# iostm32f205zx register map
Registers are 32-bit, access not given, no defined reset value unless marked. A register's access mark holds for its fields unless they carry their own. Addresses are absolute; registers are grouped by the start of their names; [hi:lo] are bit positions.

## TIM6
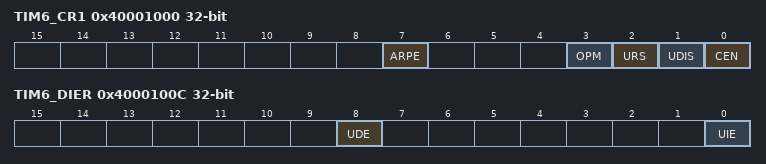
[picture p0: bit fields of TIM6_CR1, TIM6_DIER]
0x40001000 TIM6_CR1
  [7] ARPE, [3] OPM, [2] URS, [1] UDIS, [0] CEN
0x40001004 TIM6_CR2
  [6:4] MMS
0x4000100C TIM6_DIER
  [8] UDE, [0] UIE
0x40001010 TIM6_SR
  [0] UIF
0x40001014 TIM6_EGR
  [0] UG
0x40001024 TIM6_CNT
  [15:0] CNT
0x40001028 TIM6_PSC
  [15:0] PSC
0x4000102C TIM6_ARR
  [15:0] ARR

## TIM7
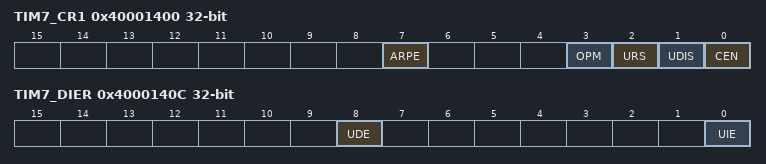
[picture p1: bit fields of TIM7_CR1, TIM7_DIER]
0x40001400 TIM7_CR1
  [7] ARPE, [3] OPM, [2] URS, [1] UDIS, [0] CEN
0x40001404 TIM7_CR2
  [6:4] MMS
0x4000140C TIM7_DIER
  [8] UDE, [0] UIE
0x40001410 TIM7_SR
  [0] UIF
0x40001414 TIM7_EGR
  [0] UG
0x40001424 TIM7_CNT
  [15:0] CNT
0x40001428 TIM7_PSC
  [15:0] PSC
0x4000142C TIM7_ARR
  [15:0] ARR

## TIM9
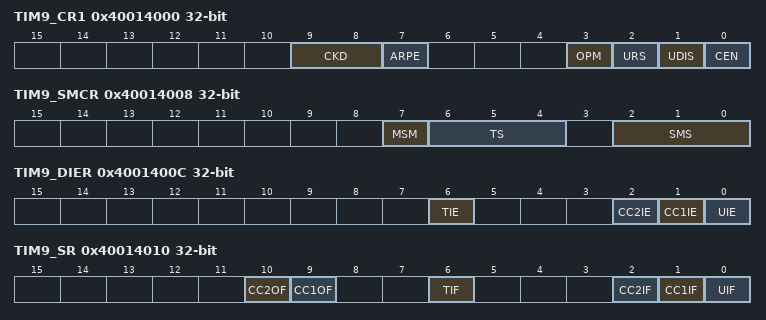
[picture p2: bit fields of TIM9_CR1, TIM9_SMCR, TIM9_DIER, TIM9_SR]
0x40014000 TIM9_CR1
  [9:8] CKD, [7] ARPE, [3] OPM, [2] URS, [1] UDIS, [0] CEN
0x40014004 TIM9_CR2
  [6:4] MMS
0x40014008 TIM9_SMCR
  [7] MSM, [6:4] TS, [2:0] SMS
0x4001400C TIM9_DIER
  [6] TIE, [2] CC2IE, [1] CC1IE, [0] UIE
0x40014010 TIM9_SR
  [10] CC2OF, [9] CC1OF, [6] TIF, [2] CC2IF, [1] CC1IF, [0] UIF
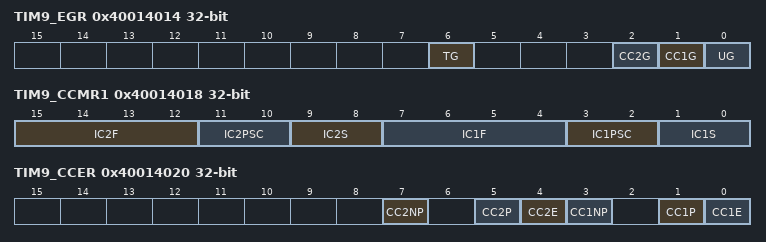
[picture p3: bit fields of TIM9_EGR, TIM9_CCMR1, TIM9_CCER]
0x40014014 TIM9_EGR
  [6] TG, [2] CC2G, [1] CC1G, [0] UG
0x40014018 TIM9_CCMR1
  [15:12] IC2F, [11:10] IC2PSC, [9:8] IC2S, [7:4] IC1F, [3:2] IC1PSC, [1:0] IC1S
0x40014018 TIM9_OCMR1
0x40014020 TIM9_CCER
  [7] CC2NP, [5] CC2P, [4] CC2E, [3] CC1NP, [1] CC1P, [0] CC1E
0x40014024 TIM9_CNT
  [15:0] CNT
0x40014028 TIM9_PSC
  [15:0] PSC
0x4001402C TIM9_ARR
  [15:0] ARR
0x40014034 TIM9_CCR1
  [15:0] CCR
0x40014038 TIM9_CCR2
  [15:0] CCR

## TIM12
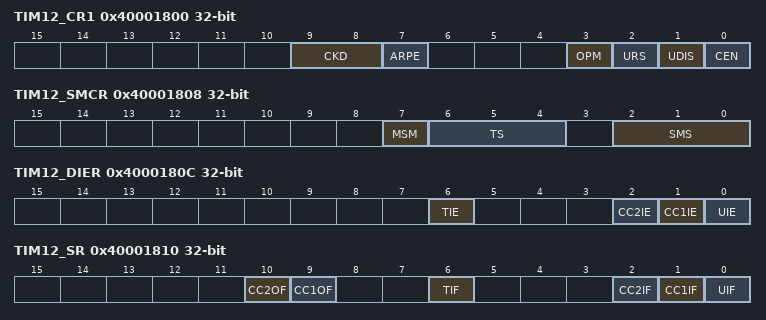
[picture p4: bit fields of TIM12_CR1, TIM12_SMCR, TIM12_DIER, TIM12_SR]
0x40001800 TIM12_CR1
  [9:8] CKD, [7] ARPE, [3] OPM, [2] URS, [1] UDIS, [0] CEN
0x40001804 TIM12_CR2
  [6:4] MMS
0x40001808 TIM12_SMCR
  [7] MSM, [6:4] TS, [2:0] SMS
0x4000180C TIM12_DIER
  [6] TIE, [2] CC2IE, [1] CC1IE, [0] UIE
0x40001810 TIM12_SR
  [10] CC2OF, [9] CC1OF, [6] TIF, [2] CC2IF, [1] CC1IF, [0] UIF
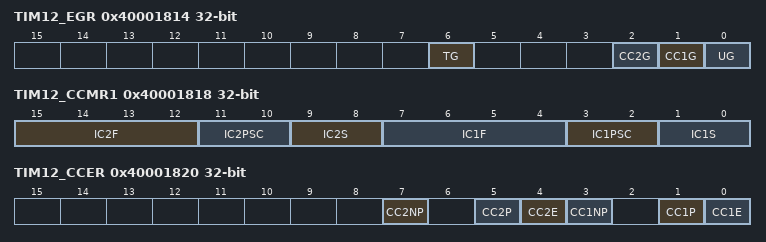
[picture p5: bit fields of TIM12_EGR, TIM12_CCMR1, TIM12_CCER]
0x40001814 TIM12_EGR
  [6] TG, [2] CC2G, [1] CC1G, [0] UG
0x40001818 TIM12_CCMR1
  [15:12] IC2F, [11:10] IC2PSC, [9:8] IC2S, [7:4] IC1F, [3:2] IC1PSC, [1:0] IC1S
0x40001818 TIM12_OCMR1
0x40001820 TIM12_CCER
  [7] CC2NP, [5] CC2P, [4] CC2E, [3] CC1NP, [1] CC1P, [0] CC1E
0x40001824 TIM12_CNT
  [15:0] CNT
0x40001828 TIM12_PSC
  [15:0] PSC
0x4000182C TIM12_ARR
  [15:0] ARR
0x40001834 TIM12_CCR1
  [15:0] CCR
0x40001838 TIM12_CCR2
  [15:0] CCR

## TIM10
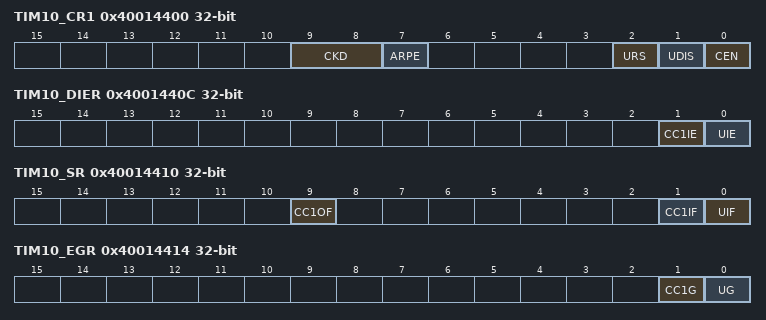
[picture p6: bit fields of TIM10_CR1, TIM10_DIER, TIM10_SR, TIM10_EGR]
0x40014400 TIM10_CR1
  [9:8] CKD, [7] ARPE, [2] URS, [1] UDIS, [0] CEN
0x4001440C TIM10_DIER
  [1] CC1IE, [0] UIE
0x40014410 TIM10_SR
  [9] CC1OF, [1] CC1IF, [0] UIF
0x40014414 TIM10_EGR
  [1] CC1G, [0] UG
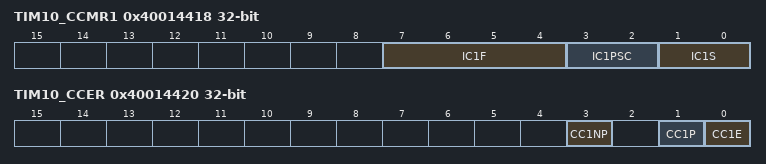
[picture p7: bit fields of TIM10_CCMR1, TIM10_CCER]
0x40014418 TIM10_CCMR1
  [7:4] IC1F, [3:2] IC1PSC, [1:0] IC1S
0x40014418 TIM10_OCMR1
0x40014420 TIM10_CCER
  [3] CC1NP, [1] CC1P, [0] CC1E
0x40014424 TIM10_CNT
  [15:0] CNT
0x40014428 TIM10_PSC
  [15:0] PSC
0x4001442C TIM10_ARR
  [15:0] ARR
0x40014434 TIM10_CCR1
  [15:0] CCR

## TIM11
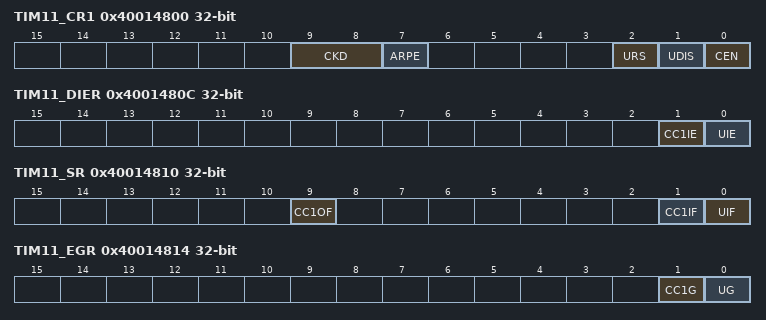
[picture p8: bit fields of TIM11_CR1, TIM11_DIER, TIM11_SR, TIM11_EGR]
0x40014800 TIM11_CR1
  [9:8] CKD, [7] ARPE, [2] URS, [1] UDIS, [0] CEN
0x4001480C TIM11_DIER
  [1] CC1IE, [0] UIE
0x40014810 TIM11_SR
  [9] CC1OF, [1] CC1IF, [0] UIF
0x40014814 TIM11_EGR
  [1] CC1G, [0] UG
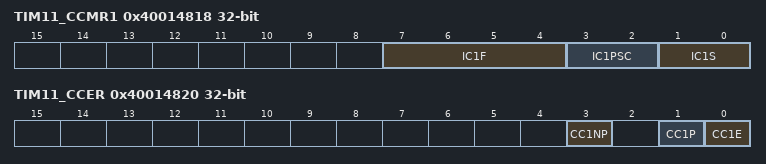
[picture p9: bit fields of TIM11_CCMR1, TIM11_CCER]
0x40014818 TIM11_CCMR1
  [7:4] IC1F, [3:2] IC1PSC, [1:0] IC1S
0x40014818 TIM11_OCMR1
0x40014820 TIM11_CCER
  [3] CC1NP, [1] CC1P, [0] CC1E
0x40014824 TIM11_CNT
  [15:0] CNT
0x40014828 TIM11_PSC
  [15:0] PSC
0x4001482C TIM11_ARR
  [15:0] ARR
0x40014834 TIM11_CCR1
  [15:0] CCR
0x40014850 TIM11_OR
  [1:0] TI1_RMP

## TIM13
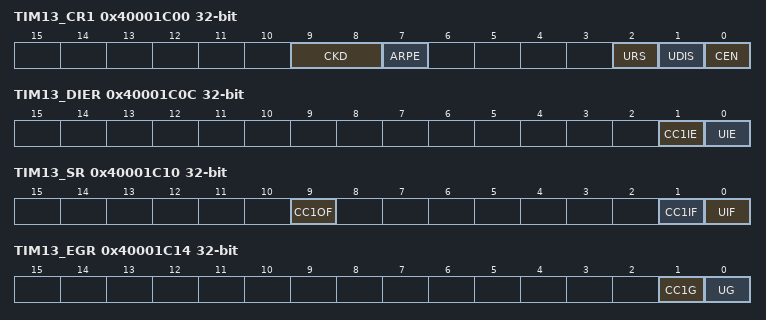
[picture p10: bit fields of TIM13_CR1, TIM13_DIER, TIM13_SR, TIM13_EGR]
0x40001C00 TIM13_CR1
  [9:8] CKD, [7] ARPE, [2] URS, [1] UDIS, [0] CEN
0x40001C0C TIM13_DIER
  [1] CC1IE, [0] UIE
0x40001C10 TIM13_SR
  [9] CC1OF, [1] CC1IF, [0] UIF
0x40001C14 TIM13_EGR
  [1] CC1G, [0] UG
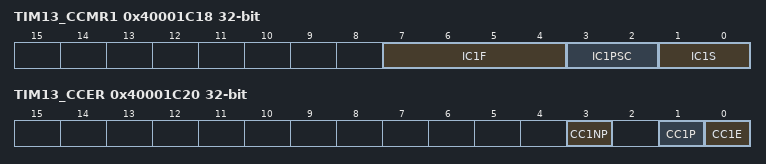
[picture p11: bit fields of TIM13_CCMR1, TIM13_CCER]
0x40001C18 TIM13_CCMR1
  [7:4] IC1F, [3:2] IC1PSC, [1:0] IC1S
0x40001C18 TIM13_OCMR1
0x40001C20 TIM13_CCER
  [3] CC1NP, [1] CC1P, [0] CC1E
0x40001C24 TIM13_CNT
  [15:0] CNT
0x40001C28 TIM13_PSC
  [15:0] PSC
0x40001C2C TIM13_ARR
  [15:0] ARR
0x40001C34 TIM13_CCR1
  [15:0] CCR
